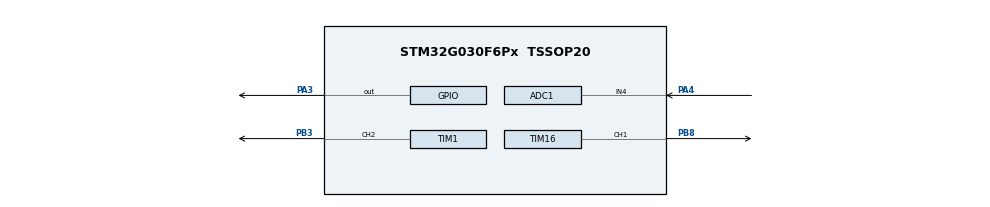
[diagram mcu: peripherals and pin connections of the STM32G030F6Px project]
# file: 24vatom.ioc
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ADC1.AWD1HighThreshold=280
ADC1.AWD1ITMode=ENABLE
ADC1.Channel-0\#ChannelRegularConversion=ADC_CHANNEL_4
ADC1.ContinuousConvMode=ENABLE
ADC1.EnableAnalogWatchDog1=true
ADC1.ExternalTrigConv=ADC_SOFTWARE_START
ADC1.NbrOfConversionFlag=1
ADC1.Rank-0\#ChannelRegularConversion=1
ADC1.SamplingTime-0\#ChannelRegularConversion=ADC_SAMPLINGTIME_COMMON_1
ADC1.SamplingTimeCommon1=ADC_SAMPLETIME_160CYCLES_5
ADC1.SamplingTimeCommon2=ADC_SAMPLETIME_160CYCLES_5
ADC1.SelectedChannel=ADC_CHANNEL_4|ADC_CHANNEL_TEMPSENSOR|ADC_CHANNEL_VREFINT
ADC1.master=1
Mcu.Family=STM32G0
Mcu.Name=STM32G030F6Px
Mcu.Package=TSSOP20
NVIC.ADC1_IRQn=true\:0\:0\:false\:false\:true\:true\:true\:true
PA13.Mode=Serial_Wire
PA13.Signal=SYS_SWDIO
PA14-BOOT0.Mode=Serial_Wire
PA14-BOOT0.Signal=SYS_SWCLK
PA14-BOOT0__PA15.StandardMode=true
PA3.Signal=GPIO_Output
PA4.Mode=IN4
PA4.Signal=ADC1_IN4
PB0__PB1__PB2__PA8.StandardMode=true
PB3.Signal=S_TIM1_CH2
PB3__PB4__PB5__PB6.StandardMode=true
PB7__PB8.StandardMode=true
PB8.GPIO_FM8=__NULL
PB8.GPIO_Speed=GPIO_SPEED_FREQ_MEDIUM
PB8.Signal=S_TIM16_CH1
PC14-OSC32_IN\ (PC14)__PB9.StandardMode=true
ProjectManager.HeapSize=0x200
ProjectManager.StackSize=0x400
ProjectManager.TargetToolchain=MDK-ARM V5.32
RCC.ADCFreq_Value=64000000
RCC.AHBFreq_Value=64000000
RCC.CortexFreq_Value=64000000
RCC.EXTERNAL_CLOCK_VALUE=12288000
RCC.HCLKFreq_Value=64000000
RCC.HSE_VALUE=8000000
RCC.HSI_VALUE=16000000
RCC.LSE_VALUE=32768
RCC.SYSCLKFreq_VALUE=64000000
RCC.SYSCLKSource=RCC_SYSCLKSOURCE_PLLCLK
RCC.VCOOutputFreq_Value=128000000
SH.S_TIM16_CH1.0=TIM16_CH1,PWM Generation1 CH1
SH.S_TIM1_CH2.0=TIM1_CH2,PWM Generation2 CH2
TIM1.AutoReloadPreload=TIM_AUTORELOAD_PRELOAD_ENABLE
TIM1.Channel-PWM\ Generation2\ CH2=TIM_CHANNEL_2
TIM1.Period=99
TIM1.Prescaler=719
TIM1.Pulse-PWM\ Generation2\ CH2=100
TIM16.AutoReloadPreload=TIM_AUTORELOAD_PRELOAD_ENABLE
TIM16.Channel=TIM_CHANNEL_1
TIM16.OCFastMode_PWM=TIM_OCFAST_ENABLE
TIM16.Period=3
TIM16.Prescaler=8
TIM16.Pulse=100
TIM16.RepetitionCounter=0
VP_ADC1_TempSens_Input.Mode=IN-TempSens
VP_ADC1_Vref_Input.Mode=IN-Vrefint
VP_TIM16_VS_ClockSourceINT.Mode=Enable_Timer
VP_TIM1_VS_ClockSourceINT.Mode=Internal
board=custom

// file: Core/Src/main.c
/* USER CODE BEGIN Header */
/**
  ******************************************************************************
  * @file           : main.c
  * @brief          : Main program body
  ******************************************************************************
  * @attention
  *
  * Copyright (c) 2024 STMicroelectronics.
  * All rights reserved.
  *
  * This software is licensed under terms that can be found in the LICENSE file
  * in the root directory of this software component.
  * If no LICENSE file comes with this software, it is provided AS-IS.
  *
  ******************************************************************************
  */
/* USER CODE END Header */
#include "main.h"
#include "adc.h"
#include "tim.h"
#include "gpio.h"

/* USER CODE BEGIN Includes */
#include "SEGGER_RTT.h"
#include "stdio.h"

/* USER CODE END Includes */

void SystemClock_Config(void);

int main(void)
{

  /* MCU Configuration--------------------------------------------------------*/

  /* Reset of all peripherals, Initializes the Flash interface and the Systick. */
  LL_APB2_GRP1_EnableClock(LL_APB2_GRP1_PERIPH_SYSCFG);
  LL_APB1_GRP1_EnableClock(LL_APB1_GRP1_PERIPH_PWR);

  /* SysTick_IRQn interrupt configuration */
  NVIC_SetPriority(SysTick_IRQn, 3);

  /* Configure the system clock */
  SystemClock_Config();

  /* Initialize all configured peripherals */
  MX_GPIO_Init();
  MX_ADC1_Init();
  MX_TIM16_Init();
  MX_TIM1_Init();
  /* USER CODE BEGIN 2 */
	SEGGER_RTT_Init();
	SEGGER_RTT_printf(0, "Hello world!\r\n");
	Activate_ADC();
	LL_ADC_REG_StartConversion(ADC1);
	TIM16_StartPWM();
	TIM1_StartPWM();
  /* USER CODE END 2 */

  /* Infinite loop */
  while (1)
  {

  }
}

void SystemClock_Config(void)
{
  LL_FLASH_SetLatency(LL_FLASH_LATENCY_2);
  while(LL_FLASH_GetLatency() != LL_FLASH_LATENCY_2)
  {
  }

  /* HSI configuration and activation */
  LL_RCC_HSI_Enable();
  while(LL_RCC_HSI_IsReady() != 1)
  {
  }

  /* Main PLL configuration and activation */
  LL_RCC_PLL_ConfigDomain_SYS(LL_RCC_PLLSOURCE_HSI, LL_RCC_PLLM_DIV_1, 8, LL_RCC_PLLR_DIV_2);
  LL_RCC_PLL_Enable();
  LL_RCC_PLL_EnableDomain_SYS();
  while(LL_RCC_PLL_IsReady() != 1)
  {
  }

  /* Set AHB prescaler*/
  LL_RCC_SetAHBPrescaler(LL_RCC_SYSCLK_DIV_1);

  /* Sysclk activation on the main PLL */
  LL_RCC_SetSysClkSource(LL_RCC_SYS_CLKSOURCE_PLL);
  while(LL_RCC_GetSysClkSource() != LL_RCC_SYS_CLKSOURCE_STATUS_PLL)
  {
  }

  /* Set APB1 prescaler*/
  LL_RCC_SetAPB1Prescaler(LL_RCC_APB1_DIV_1);

  LL_Init1msTick(64000000);

  /* Update CMSIS variable (which can be updated also through SystemCoreClockUpdate function) */
  LL_SetSystemCoreClock(64000000);
}

/* USER CODE BEGIN 4 */
int stdout_putchar (int ch) {
  return (SEGGER_RTT_PutChar(0, ch));
}
/* USER CODE END 4 */

void Error_Handler(void)
{
  __disable_irq();
  while (1)
  {
  }
}
